# MKM34Z7 register map
Vendor: Freescale Semiconductor, Inc.; Series: Kinetis_M; File version: 1.6
CPU: CM0PLUS r0p0, little endian, no MPU, no FPU, VTOR, 2 interrupt priority bits
Registers are 32-bit, read-write, reset 0x0 unless marked. A register's access mark holds for its fields unless they carry their own. Offsets are from the block's base; [hi:lo] are bit positions.

## GPIOA — General Purpose Input/Output
Base 0x400FF000; register names take the prefix GPIOA_
0x00 PDOR 8-bit — Port Data Output Register
  [7:0] PDO — Port Data Output
    0=Logic level 0 is driven on pin, provided pin is configured for general-purpose output; 1=Logic level 1 is driven on pin, provided pin is configured for general-purpose output
0x04 PSOR 8-bit wo — Port Set Output Register
  [7:0] PTSO — Port Set Output
    0=Corresponding bit in PDORn does not change; 1=Corresponding bit in PDORn is set to logic 1
0x08 PCOR 8-bit wo — Port Clear Output Register
  [7:0] PTCO — Port Clear Output
    0=Corresponding bit in PDORn does not change; 1=Corresponding bit in PDORn is cleared to logic 0
0x0C PTOR 8-bit wo — Port Toggle Output Register
  [7:0] PTTO — Port Toggle Output
    0=Corresponding bit in PDORn does not change; 1=Corresponding bit in PDORn is set to the inverse of its existing logic state
0x10 PDIR 8-bit ro — Port Data Input Register
  [7:0] PDI — Port Data Input
    0=Pin logic level is logic 0, or is not configured for use by digital function; 1=Pin logic level is logic 1
0x14 PDDR 8-bit — Port Data Direction Register
  [7:0] PDD — Port Data Direction
    0=Pin is configured as general-purpose input, for the GPIO function; 1=Pin is configured as general-purpose output, for the GPIO function
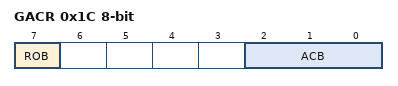
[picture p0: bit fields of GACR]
0x1C GACR 8-bit — GPIO Attribute Checker Register
  [7] ROB — Read-Only Byte
    0=Writes to the ACB are allowed; 1=Writes to the ACB are ignored
  [2:0] ACB — Attribute Check Byte
    0=User nonsecure: Read + Write; User Secure: Read + Write; Privileged Secure: Read + Write; 1=User nonsecure: Read; User Secure: Read + Write; Privileged Secure: Read + Write; 2=User nonsecure: None; User Secure: Read + Write; Privileged Secure: Read + Write; 3=User nonsecure: Read; User Secure: Read; Privileged Secure: Read + Write; 4=User nonsecure: None; User Secure: Read; Privileged Secure: Read + Write; 5=User nonsecure: None; User Secure: None; Privileged Secure: Read + Write; 6=User nonsecure: None; User Secure: None; Privileged Secure: Read; 7=User nonsecure: None; User Secure: None; Privileged Secure: None

## GPIOB — General Purpose Input/Output
Base 0x400FF001; register names take the prefix GPIOB_
Registers as GPIOA.

## GPIOC — General Purpose Input/Output
Base 0x400FF002; register names take the prefix GPIOC_
Registers as GPIOA.

## GPIOD — General Purpose Input/Output
Base 0x400FF003; register names take the prefix GPIOD_
Registers as GPIOA.

## GPIOE — General Purpose Input/Output
Base 0x400FF040; register names take the prefix GPIOE_
Registers as GPIOA.

## GPIOF — General Purpose Input/Output
Base 0x400FF041; register names take the prefix GPIOF_
Registers as GPIOA.

## GPIOG — General Purpose Input/Output
Base 0x400FF042; register names take the prefix GPIOG_
Registers as GPIOA.

## GPIOH — General Purpose Input/Output
Base 0x400FF043; register names take the prefix GPIOH_
Registers as GPIOA.

## GPIOI — General Purpose Input/Output
Base 0x400FF080; register names take the prefix GPIOI_
Registers as GPIOA.

## GPIOJ — General Purpose Input/Output
Base 0x400FF081; register names take the prefix GPIOJ_
Registers as GPIOA.

## GPIOK — General Purpose Input/Output
Base 0x400FF082; register names take the prefix GPIOK_
Registers as GPIOA.

## GPIOL — General Purpose Input/Output
Base 0x400FF083; register names take the prefix GPIOL_
Registers as GPIOA.

## GPIOM — General Purpose Input/Output
Base 0x400FF0C0; register names take the prefix GPIOM_
Registers as GPIOA.
